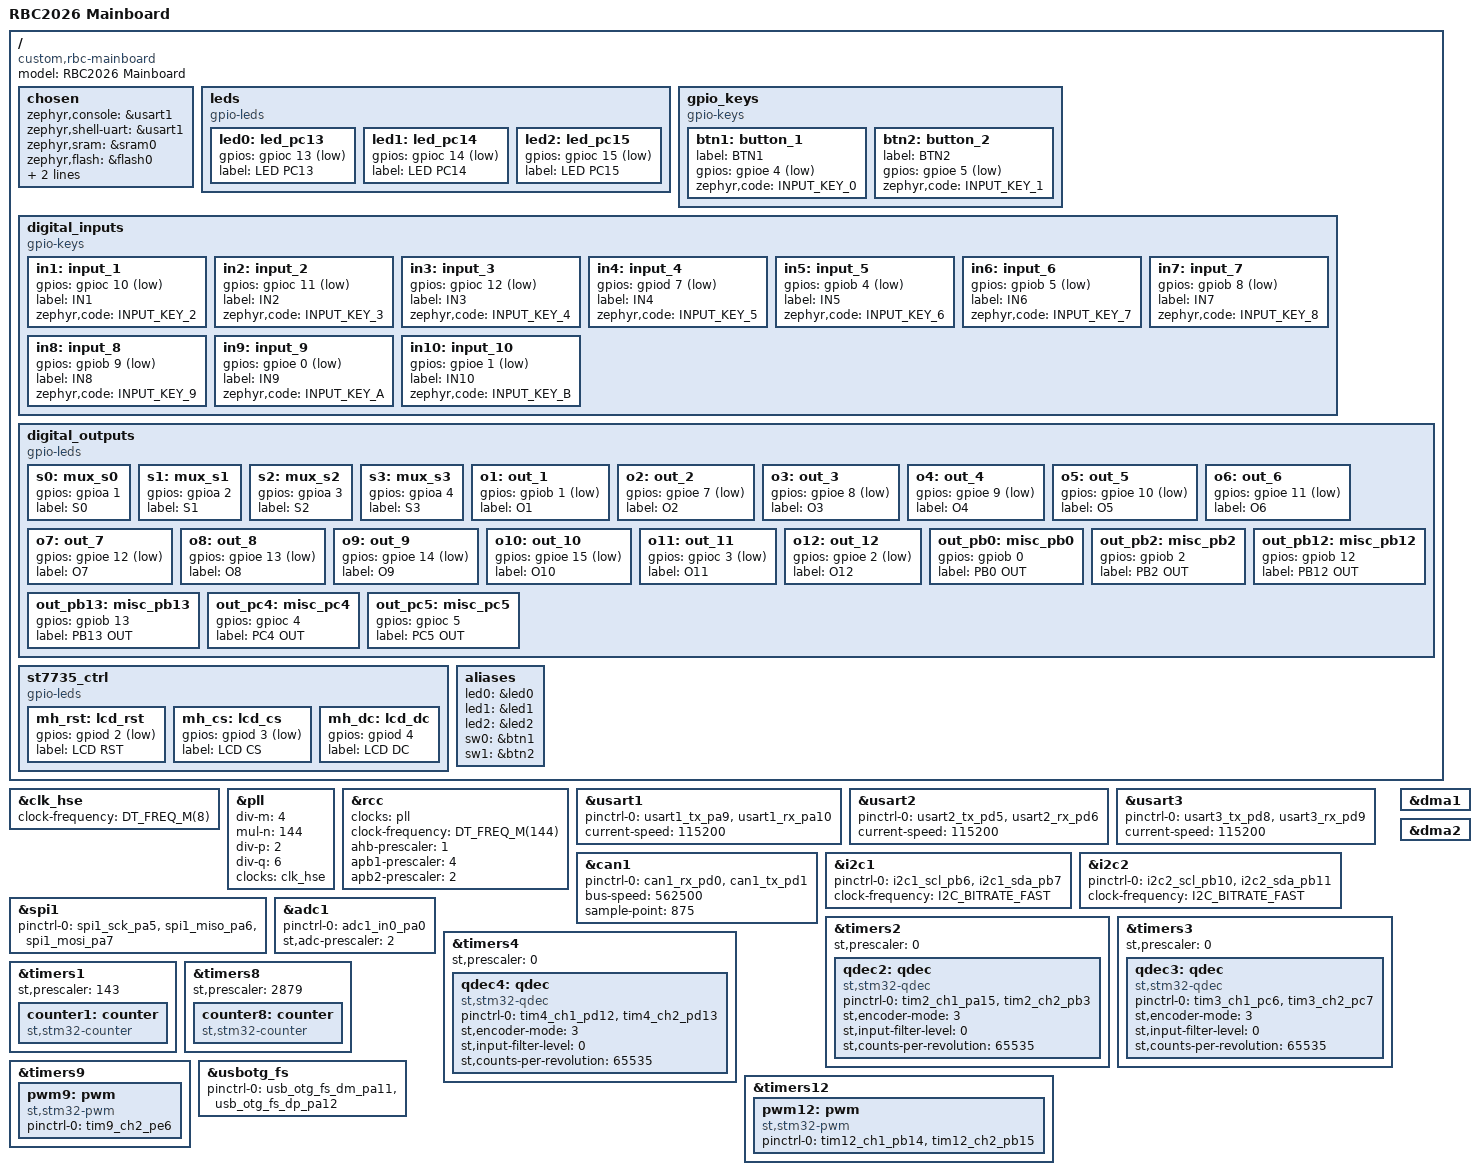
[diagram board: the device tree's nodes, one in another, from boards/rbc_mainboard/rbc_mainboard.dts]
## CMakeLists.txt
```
cmake_minimum_required(VERSION 3.20)

# Tim custom board definition trong thu muc boards/ cua project
list(APPEND BOARD_ROOT ${CMAKE_CURRENT_SOURCE_DIR})

find_package(Zephyr REQUIRED HINTS $ENV{ZEPHYR_BASE})
project(rbc_r1_blinky)

target_sources(app PRIVATE
    src/main.c
    src/bno055.c
    src/bno055_zephyr.c
    src/pca9685_zephyr.c
)

# Include src/ de bno055.c tim thay bno055.h va bno055_zephyr.h
target_include_directories(app PRIVATE src)
```

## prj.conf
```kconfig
# ── Core ──────────────────────────────────────────
CONFIG_GPIO=y
CONFIG_FPU=y
CONFIG_FPU_SHARING=y
CONFIG_CBPRINTF_FP_SUPPORT=y

# ── Compiler: toi uu toc do ──────────────────────
CONFIG_SPEED_OPTIMIZATIONS=y

# ── UART ──────────────────────────────────────────
CONFIG_SERIAL=y
CONFIG_UART_INTERRUPT_DRIVEN=y

# ── CAN ───────────────────────────────────────────
CONFIG_CAN=y

# ── I2C ───────────────────────────────────────────
CONFIG_I2C=y

# ── SPI ───────────────────────────────────────────
CONFIG_SPI=y

# ── ADC ───────────────────────────────────────────
CONFIG_ADC=y

# ── Math ──────────────────────────────────────────
# Picolibc nhe hon newlib 5-10x, la default cua Zephyr
CONFIG_PICOLIBC=y
CONFIG_PICOLIBC_IO_FLOAT=y

# ── Scheduler: multi-queue cho multi-priority tot hon ──
CONFIG_SCHED_MULTIQ=y

# ── Stack / Heap ──────────────────────────────────
# main thread: chi LED blink, giam stack
CONFIG_MAIN_STACK_SIZE=512
CONFIG_HEAP_MEM_POOL_SIZE=2048

# ── Atomic support ────────────────────────────────
# Da co san trong Zephyr kernel, khong can them config
# CONFIG_ATOMIC_OPERATIONS_BUILTIN enabled by default

# ── Thread name (de debug voi Zephyr shell) ────────
CONFIG_THREAD_NAME=y

# ── Log: tat trong production (giam latency) ──────
CONFIG_LOG=n
```

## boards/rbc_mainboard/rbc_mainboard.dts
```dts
/*
 * RBC2026 Mainboard - Custom board definition
 * Chip: STM32F407VGT6, LQFP100, HSE 8MHz
 * Chuyen tu file: RBC2026_MAINBOARD_OK.ioc
 *
 * SPDX-License-Identifier: Apache-2.0
 */

/dts-v1/;
#include <st/f4/stm32f407Xg.dtsi>
#include <st/f4/stm32f407v(e-g)tx-pinctrl.dtsi>
#include <zephyr/dt-bindings/input/input-event-codes.h>
#include <zephyr/dt-bindings/pwm/pwm.h>

/ {
	model = "RBC2026 Mainboard";
	compatible = "custom,rbc-mainboard";

	chosen {
		zephyr,console = &usart1;
		zephyr,shell-uart = &usart1;
		zephyr,sram = &sram0;
		zephyr,flash = &flash0;
		zephyr,dtcm = &ccm0;
		zephyr,canbus = &can1;
	};

	/*
	 * ====================
	 *  LEDs (PC13, PC14, PC15) - active LOW
	 * ====================
	 */
	leds {
		compatible = "gpio-leds";

		led0: led_pc13 {
			gpios = <&gpioc 13 GPIO_ACTIVE_LOW>;
			label = "LED PC13";
		};

		led1: led_pc14 {
			gpios = <&gpioc 14 GPIO_ACTIVE_LOW>;
			label = "LED PC14";
		};

		led2: led_pc15 {
			gpios = <&gpioc 15 GPIO_ACTIVE_LOW>;
			label = "LED PC15";
		};
	};

	/*
	 * ====================
	 *  Buttons (PE4 = btn1, PE5 = btn2)
	 * ====================
	 */
	gpio_keys {
		compatible = "gpio-keys";

		btn1: button_1 {
			label = "BTN1";
			gpios = <&gpioe 4 (GPIO_PULL_UP | GPIO_ACTIVE_LOW)>;
			zephyr,code = <INPUT_KEY_0>;
		};

		btn2: button_2 {
			label = "BTN2";
			gpios = <&gpioe 5 (GPIO_PULL_UP | GPIO_ACTIVE_LOW)>;
			zephyr,code = <INPUT_KEY_1>;
		};
	};

	/*
	 * ====================
	 *  Digital Inputs (in1..in10)
	 *  Dung cho limit switch, sensor, v.v.
	 * ====================
	 */
	digital_inputs {
		compatible = "gpio-keys";

		in1: input_1 {
			gpios = <&gpioc 10 GPIO_ACTIVE_LOW>;
			label = "IN1";
			zephyr,code = <INPUT_KEY_2>;
		};
		in2: input_2 {
			gpios = <&gpioc 11 GPIO_ACTIVE_LOW>;	
			label = "IN2";
			zephyr,code = <INPUT_KEY_3>;
		};
		in3: input_3 {
			gpios = <&gpioc 12 GPIO_ACTIVE_LOW>;
			label = "IN3";
			zephyr,code = <INPUT_KEY_4>;
		};
		in4: input_4 {
			gpios = <&gpiod 7 GPIO_ACTIVE_LOW>;
			label = "IN4";
			zephyr,code = <INPUT_KEY_5>;
		};
		in5: input_5 {
			gpios = <&gpiob 4 GPIO_ACTIVE_LOW>;
			label = "IN5";
			zephyr,code = <INPUT_KEY_6>;
		};
		in6: input_6 {
			gpios = <&gpiob 5 GPIO_ACTIVE_LOW>;
			label = "IN6";
			zephyr,code = <INPUT_KEY_7>;
		};
		in7: input_7 {
			gpios = <&gpiob 8 GPIO_ACTIVE_LOW>;
			label = "IN7";
			zephyr,code = <INPUT_KEY_8>;
		};
		in8: input_8 {
			gpios = <&gpiob 9 GPIO_ACTIVE_LOW>;
			label = "IN8";
			zephyr,code = <INPUT_KEY_9>;
		};
		in9: input_9 {
			gpios = <&gpioe 0 GPIO_ACTIVE_LOW>;
			label = "IN9";
			zephyr,code = <INPUT_KEY_A>;
		};
		in10: input_10 {
			gpios = <&gpioe 1 GPIO_ACTIVE_LOW>;
			label = "IN10";
			zephyr,code = <INPUT_KEY_B>;
		};
	};

	/*
	 * ====================
	 *  Digital Outputs (s0..s3, o1..o12)
	 *  Dung cho relay, solenoid, motor direction, v.v.
	 * ====================
	 */
	digital_outputs {
		compatible = "gpio-leds";

		/* Multiplexer select lines */
		s0: mux_s0 { gpios = <&gpioa 1 GPIO_ACTIVE_HIGH>; label = "S0"; };
		s1: mux_s1 { gpios = <&gpioa 2 GPIO_ACTIVE_HIGH>; label = "S1"; };
		s2: mux_s2 { gpios = <&gpioa 3 GPIO_ACTIVE_HIGH>; label = "S2"; };
		s3: mux_s3 { gpios = <&gpioa 4 GPIO_ACTIVE_HIGH>; label = "S3"; };

		/* General outputs */
		o1:  out_1  { gpios = <&gpiob 1 GPIO_ACTIVE_LOW>;  label = "O1"; };
		o2:  out_2  { gpios = <&gpioe 7 GPIO_ACTIVE_LOW>;  label = "O2"; };
		o3:  out_3  { gpios = <&gpioe 8 GPIO_ACTIVE_LOW>;  label = "O3"; };
		o4:  out_4  { gpios = <&gpioe 9 GPIO_ACTIVE_LOW>;  label = "O4"; };
		o5:  out_5  { gpios = <&gpioe 10 GPIO_ACTIVE_LOW>; label = "O5"; };
		o6:  out_6  { gpios = <&gpioe 11 GPIO_ACTIVE_LOW>; label = "O6"; };
		o7:  out_7  { gpios = <&gpioe 12 GPIO_ACTIVE_LOW>; label = "O7"; };
		o8:  out_8  { gpios = <&gpioe 13 GPIO_ACTIVE_LOW>; label = "O8"; };
		o9:  out_9  { gpios = <&gpioe 14 GPIO_ACTIVE_LOW>; label = "O9"; };
		o10: out_10 { gpios = <&gpioe 15 GPIO_ACTIVE_LOW>; label = "O10";};
		o11: out_11 { gpios = <&gpioc 3 GPIO_ACTIVE_LOW>; label = "O11";};
		o12: out_12 { gpios = <&gpioe 2 GPIO_ACTIVE_LOW>; label = "O12";};

		/* Misc outputs */
		out_pb0:  misc_pb0  { gpios = <&gpiob 0 GPIO_ACTIVE_HIGH>;  label = "PB0 OUT"; };
		out_pb2:  misc_pb2  { gpios = <&gpiob 2 GPIO_ACTIVE_HIGH>;  label = "PB2 OUT"; };
		out_pb12: misc_pb12 { gpios = <&gpiob 12 GPIO_ACTIVE_HIGH>; label = "PB12 OUT"; };
		out_pb13: misc_pb13 { gpios = <&gpiob 13 GPIO_ACTIVE_HIGH>; label = "PB13 OUT"; };
		out_pc4:  misc_pc4  { gpios = <&gpioc 4 GPIO_ACTIVE_HIGH>;  label = "PC4 OUT"; };
		out_pc5:  misc_pc5  { gpios = <&gpioc 5 GPIO_ACTIVE_HIGH>;  label = "PC5 OUT"; };
	};

	/*
	 * ====================
	 *  ST7735 LCD control pins (SPI1 + GPIO)
	 * ====================
	 */
	st7735_ctrl {
		compatible = "gpio-leds";
		mh_rst: lcd_rst { gpios = <&gpiod 2 GPIO_ACTIVE_LOW>;  label = "LCD RST"; };
		mh_cs:  lcd_cs  { gpios = <&gpiod 3 GPIO_ACTIVE_LOW>;  label = "LCD CS"; };
		mh_dc:  lcd_dc  { gpios = <&gpiod 4 GPIO_ACTIVE_HIGH>; label = "LCD DC"; };
	};

	/*
	 * ====================
	 *  Aliases
	 * ====================
	 */
	aliases {
		led0 = &led0;
		led1 = &led1;
		led2 = &led2;
		sw0 = &btn1;
		sw1 = &btn2;
	};
};

/*
 * ====================
 *  Clock: HSE 8MHz -> PLL -> SYSCLK 144MHz
 *  (IOC: PLLM=4, PLLN=144, PLLP=2 -> 8/4*144/2 = 144MHz)
 *  APB1 = 36MHz (/4), APB2 = 72MHz (/2)
 * ====================
 */
&clk_hse {
	clock-frequency = <DT_FREQ_M(8)>;
	status = "okay";
};

&pll {
	div-m = <4>;
	mul-n = <144>;
	div-p = <2>;
	div-q = <6>;
	clocks = <&clk_hse>;
	status = "okay";
};

&rcc {
	clocks = <&pll>;
	clock-frequency = <DT_FREQ_M(144)>;
	ahb-prescaler = <1>;
	apb1-prescaler = <4>;
	apb2-prescaler = <2>;
};

/*
 * ====================
 *  USART1: PA9(TX) PA10(RX) - Console/Debug
 * ====================
 */
&usart1 {
	pinctrl-0 = <&usart1_tx_pa9 &usart1_rx_pa10>;
	pinctrl-names = "default";
	current-speed = <115200>;
	status = "okay";
};

/*
 * ====================
 *  USART2: PD5(TX) PD6(RX) - HC12 / ESP
 * ====================
 */
&usart2 {
	pinctrl-0 = <&usart2_tx_pd5 &usart2_rx_pd6>;
	pinctrl-names = "default";
	current-speed = <115200>;
	status = "okay";
};

/*
 * ====================
 *  USART3: PD8(TX) PD9(RX) - DMA RX
 * ====================
 */
&usart3 {
	pinctrl-0 = <&usart3_tx_pd8 &usart3_rx_pd9>;
	pinctrl-names = "default";
	current-speed = <115200>;
	status = "okay";
};

/*
 * ====================
 *  CAN1: PD0(RX) PD1(TX)
 *  IOC: Prescaler=4, BS1=13TQ, BS2=2TQ -> 562.5kbps @ APB1=36MHz
 * ====================
 */
&can1 {
	pinctrl-0 = <&can1_rx_pd0 &can1_tx_pd1>;
	pinctrl-names = "default";
	status = "okay";

	bus-speed = <562500>;
	sample-point = <875>;
};

/*
 * ====================
 *  I2C1: PB6(SCL) PB7(SDA) - IMU
 * ====================
 */
&i2c1 {
	pinctrl-0 = <&i2c1_scl_pb6 &i2c1_sda_pb7>;
	pinctrl-names = "default";
	clock-frequency = <I2C_BITRATE_FAST>;
	status = "okay";
};

/*
 * ====================
 *  I2C2: PB10(SCL) PB11(SDA) - PCA9685
 * ====================
 */
&i2c2 {
	pinctrl-0 = <&i2c2_scl_pb10 &i2c2_sda_pb11>;
	pinctrl-names = "default";
	clock-frequency = <I2C_BITRATE_FAST>;
	status = "okay";
};

/*
 * ====================
 *  SPI1: PA5(SCK) PA6(MISO) PA7(MOSI) - LCD ST7735
 * ====================
 */
&spi1 {
	pinctrl-0 = <&spi1_sck_pa5 &spi1_miso_pa6 &spi1_mosi_pa7>;
	pinctrl-names = "default";
	status = "okay";
};

/*
 * ====================
 *  ADC1: PA0 (IN0) - Analog input
 * ====================
 */
&adc1 {
	pinctrl-0 = <&adc1_in0_pa0>;
	pinctrl-names = "default";
	st,adc-prescaler = <2>;
	status = "okay";
};

/*
 * ====================
 *  Encoders: TIM2(PA15,PB3), TIM3(PC6,PC7), TIM4(PD12,PD13)
 *  Dung Encoder mode TI12
 * ====================
 */
&timers2 {
	status = "okay";
	st,prescaler = <0>;

	qdec2: qdec {
		compatible = "st,stm32-qdec";
		status = "okay";
		pinctrl-0 = <&tim2_ch1_pa15 &tim2_ch2_pb3>;
		pinctrl-names = "default";
		st,encoder-mode = <3>;
		st,input-filter-level = <0>;
		st,counts-per-revolution = <65535>;
	};
};

&timers3 {
	status = "okay";
	st,prescaler = <0>;

	qdec3: qdec {
		compatible = "st,stm32-qdec";
		status = "okay";
		pinctrl-0 = <&tim3_ch1_pc6 &tim3_ch2_pc7>;
		pinctrl-names = "default";
		st,encoder-mode = <3>;
		st,input-filter-level = <0>;
		st,counts-per-revolution = <65535>;
	};
};

&timers4 {
	status = "okay";
	st,prescaler = <0>;

	qdec4: qdec {
		compatible = "st,stm32-qdec";
		status = "okay";
		pinctrl-0 = <&tim4_ch1_pd12 &tim4_ch2_pd13>;
		pinctrl-names = "default";
		st,encoder-mode = <3>;
		st,input-filter-level = <0>;
		st,counts-per-revolution = <65535>;
	};
};

/*
 * ====================
 *  TIM1: Internal clock, Period=9999, Prescaler=143
 *  -> IRQ freq = 144MHz / (143+1) / (9999+1) = 100Hz
 * ====================
 */
&timers1 {
	status = "okay";
	st,prescaler = <143>;

	counter1: counter {
		compatible = "st,stm32-counter";
		status = "okay";
	};
};

/*
 * ====================
 *  TIM8: Internal clock, Period=9999, Prescaler=2879
 *  -> IRQ freq = 144MHz / (2879+1) / (9999+1) = 5Hz
 * ====================
 */
&timers8 {
	status = "okay";
	st,prescaler = <2879>;

	counter8: counter {
		compatible = "st,stm32-counter";
		status = "okay";
	};
};

/*
 * ====================
 *  TIM9: PWM CH2 on PE6 (Servo / Buzzer)
 * ====================
 */
&timers9 {
	status = "okay";

	pwm9: pwm {
		compatible = "st,stm32-pwm";
		status = "okay";
		pinctrl-0 = <&tim9_ch2_pe6>;
		pinctrl-names = "default";
		#pwm-cells = <3>;
	};
};

/*
 * ====================
 *  TIM12: PWM CH1(PB14), CH2(PB15) - Motor PWM
 * ====================
 */
&timers12 {
	status = "okay";

	pwm12: pwm {
		compatible = "st,stm32-pwm";
		status = "okay";
		pinctrl-0 = <&tim12_ch1_pb14 &tim12_ch2_pb15>;
		pinctrl-names = "default";
		#pwm-cells = <3>;
	};
};

/*
 * ====================
 *  USB OTG FS: PA11(DM) PA12(DP) - CDC
 * ====================
 */
zephyr_udc0: &usbotg_fs {
	pinctrl-0 = <&usb_otg_fs_dm_pa11 &usb_otg_fs_dp_pa12>;
	pinctrl-names = "default";
	status = "okay";
};

/*
 * ====================
 *  DMA
 * ====================
 */
&dma1 {
	status = "okay";
};

&dma2 {
	status = "okay";
};
```

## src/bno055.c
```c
#include "bno055.h"
#include <string.h>

uint16_t accelScale = 100;
uint16_t tempScale = 1;
uint16_t angularRateScale = 32;//32
uint16_t eulerScale = 16;
uint16_t magScale = 16;
uint16_t quaScale = (1<<14);    // 2^14

void bno055_setPage(uint8_t page) { bno055_writeData(BNO055_PAGE_ID, page); }

bno055_opmode_t bno055_getOperationMode() {
  bno055_opmode_t mode;
  bno055_readData(BNO055_OPR_MODE, &mode, 1);
  return mode;
}

void bno055_setOperationMode(bno055_opmode_t mode) {
  bno055_writeData(BNO055_OPR_MODE, mode);
  if (mode == BNO055_OPERATION_MODE_CONFIG) {
    bno055_delay(19);
  } else {
    bno055_delay(7);
  }
}

void bno055_setOperationModeConfig() {
  bno055_setOperationMode(BNO055_OPERATION_MODE_CONFIG);
}

void bno055_setOperationModeNDOF() {
  bno055_setOperationMode(BNO055_OPERATION_MODE_NDOF);
}

void bno055_setExternalCrystalUse(bool state) {
  bno055_setPage(0);
  uint8_t tmp = 0;
  bno055_readData(BNO055_SYS_TRIGGER, &tmp, 1);
  tmp |= (state == true) ? 0x80 : 0x0;
  bno055_writeData(BNO055_SYS_TRIGGER, tmp);
  bno055_delay(700);
}

void bno055_enableExternalCrystal() { bno055_setExternalCrystalUse(true); }
void bno055_disableExternalCrystal() { bno055_setExternalCrystalUse(false); }

void bno055_reset() {
  bno055_writeData(BNO055_SYS_TRIGGER, 0x20);
  bno055_delay(700);
}

int8_t bno055_getTemp() {
  bno055_setPage(0);
  uint8_t t;
  bno055_readData(BNO055_TEMP, &t, 1);
  return t;
}

void bno055_setup() {
  bno055_reset();

  uint8_t id = 0;
  bno055_readData(BNO055_CHIP_ID, &id, 1);
  if (id != BNO055_ID) {
//    printf("Can't find BNO055, id: 0x%02x. Please check your wiring.\r\n", id);
  }
  bno055_setPage(0);
  bno055_writeData(BNO055_SYS_TRIGGER, 0x0);

  // Select BNO055 config mode
  bno055_setOperationModeConfig();
  bno055_delay(10);
}

int16_t bno055_getSWRevision() {
  bno055_setPage(0);
  uint8_t buffer[2];
  bno055_readData(BNO055_SW_REV_ID_LSB, buffer, 2);
  return (int16_t)((buffer[1] << 8) | buffer[0]);
}

uint8_t bno055_getBootloaderRevision() {
  bno055_setPage(0);
  uint8_t tmp;
  bno055_readData(BNO055_BL_REV_ID, &tmp, 1);
  return tmp;
}

uint8_t bno055_getSystemStatus() {
  bno055_setPage(0);
  uint8_t tmp;
  bno055_readData(BNO055_SYS_STATUS, &tmp, 1);
  return tmp;
}

bno055_self_test_result_t bno055_getSelfTestResult() {
  bno055_setPage(0);
  uint8_t tmp;
  bno055_self_test_result_t res = {
      .mcuState = 0, .gyrState = 0, .magState = 0, .accState = 0};
  bno055_readData(BNO055_ST_RESULT, &tmp, 1);
  res.mcuState = (tmp >> 3) & 0x01;
  res.gyrState = (tmp >> 2) & 0x01;
  res.magState = (tmp >> 1) & 0x01;
  res.accState = (tmp >> 0) & 0x01;
  return res;
}

uint8_t bno055_getSystemError() {
  bno055_setPage(0);
  uint8_t tmp;
  bno055_readData(BNO055_SYS_ERR, &tmp, 1);
  return tmp;
}

bno055_calibration_state_t bno055_getCalibrationState() {
  bno055_setPage(0);
  bno055_calibration_state_t cal = {.sys = 0, .gyro = 0, .mag = 0, .accel = 0};
  uint8_t calState = 0;
  bno055_readData(BNO055_CALIB_STAT, &calState, 1);
  cal.sys = (calState >> 6) & 0x03;
  cal.gyro = (calState >> 4) & 0x03;
  cal.accel = (calState >> 2) & 0x03;
  cal.mag = calState & 0x03;
  return cal;
}


bno055_calibration_data_t bno055_getCalibrationData() {
  bno055_calibration_data_t calData;
  uint8_t buffer[22];
  bno055_opmode_t operationMode = bno055_getOperationMode();
  bno055_setOperationModeConfig();
  bno055_setPage(0);

  bno055_readData(BNO055_ACC_OFFSET_X_LSB, buffer, 22);

  // Assumes little endian processor
  memcpy(&calData.offset.accel, buffer, 6);
  memcpy(&calData.offset.mag, buffer + 6, 6);
  memcpy(&calData.offset.gyro, buffer + 12, 6);
  memcpy(&calData.radius.accel, buffer + 18, 2);
  memcpy(&calData.radius.mag, buffer + 20, 2);

  bno055_setOperationMode(operationMode);

  return calData;
}

void bno055_setCalibrationData(bno055_calibration_data_t calData) {
  uint8_t buffer[22];
  bno055_opmode_t operationMode = bno055_getOperationMode();
  bno055_setOperationModeConfig();
  bno055_setPage(0);

  // Assumes litle endian processor
  memcpy(buffer, &calData.offset.accel, 6);
  memcpy(buffer + 6, &calData.offset.mag, 6);
  memcpy(buffer + 12, &calData.offset.gyro, 6);
  memcpy(buffer + 18, &calData.radius.accel, 2);
  memcpy(buffer + 20, &calData.radius.mag, 2);

  for (uint8_t i=0; i < 22; i++) {
    // TODO(oliv4945): create multibytes write
    bno055_writeData(BNO055_ACC_OFFSET_X_LSB+i, buffer[i]);
  }

  bno055_setOperationMode(operationMode);
}

bno055_vector_t bno055_getVector(uint8_t vec) {
  bno055_setPage(0);
  uint8_t buffer[8];    // Quaternion need 8 bytes

  if (vec == BNO055_VECTOR_QUATERNION)
    bno055_readData(vec, buffer, 8);
  else
    bno055_readData(vec, buffer, 6);

  double scale = 1;

  if (vec == BNO055_VECTOR_MAGNETOMETER) {
    scale = magScale;
  } else if (vec == BNO055_VECTOR_ACCELEROMETER ||
           vec == BNO055_VECTOR_LINEARACCEL || vec == BNO055_VECTOR_GRAVITY) {
    scale = accelScale;
  } else if (vec == BNO055_VECTOR_GYROSCOPE) {
    scale = angularRateScale;
  } else if (vec == BNO055_VECTOR_EULER) {
    scale = eulerScale;
  } else if (vec == BNO055_VECTOR_QUATERNION) {
    scale = quaScale;
  }

  bno055_vector_t xyz = {.w = 0, .x = 0, .y = 0, .z = 0};
  if (vec == BNO055_VECTOR_QUATERNION) {
    xyz.w = (int16_t)((buffer[1] << 8) | buffer[0]) / scale;
    xyz.x = (int16_t)((buffer[3] << 8) | buffer[2]) / scale;
    xyz.y = (int16_t)((buffer[5] << 8) | buffer[4]) / scale;
    xyz.z = (int16_t)((buffer[7] << 8) | buffer[6]) / scale;
  } else {
    xyz.x = (int16_t)((buffer[1] << 8) | buffer[0]) / scale;
    xyz.y = (int16_t)((buffer[3] << 8) | buffer[2]) / scale;
    xyz.z = (int16_t)((buffer[5] << 8) | buffer[4]) / scale;
  }

  return xyz;
}

bno055_vector_t bno055_getVectorAccelerometer() {
  return bno055_getVector(BNO055_VECTOR_ACCELEROMETER);
}
bno055_vector_t bno055_getVectorMagnetometer() {
  return bno055_getVector(BNO055_VECTOR_MAGNETOMETER);
}
bno055_vector_t bno055_getVectorGyroscope() {
  return bno055_getVector(BNO055_VECTOR_GYROSCOPE);
}
bno055_vector_t bno055_getVectorEuler() {
  return bno055_getVector(BNO055_VECTOR_EULER);
}
bno055_vector_t bno055_getVectorLinearAccel() {
  return bno055_getVector(BNO055_VECTOR_LINEARACCEL);
}
bno055_vector_t bno055_getVectorGravity() {
  return bno055_getVector(BNO055_VECTOR_GRAVITY);
}
bno055_vector_t bno055_getVectorQuaternion() {
  return bno055_getVector(BNO055_VECTOR_QUATERNION);
}

void bno055_setAxisMap(bno055_axis_map_t axis) {
  uint8_t axisRemap = (axis.z << 4) | (axis.y << 2) | (axis.x);
  uint8_t axisMapSign = (axis.x_sign << 2) | (axis.y_sign << 1) | (axis.z_sign);
  bno055_writeData(BNO055_AXIS_MAP_CONFIG, axisRemap);
  bno055_writeData(BNO055_AXIS_MAP_SIGN, axisMapSign);
}
```

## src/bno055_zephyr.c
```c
/*
 * bno055_zephyr.c
 * HAL binding cho BNO055 su dung Zephyr I2C API.
 * Tra ve int de caller biet loi I2C.
 */
#include "bno055_zephyr.h"
#include <zephyr/kernel.h>

static const struct i2c_dt_spec *_bno055_i2c = NULL;

void bno055_assignI2C(const struct i2c_dt_spec *i2c_dev)
{
    _bno055_i2c = i2c_dev;
}

void bno055_delay(int ms)
{
    k_msleep(ms);
}

/* Tra ve 0 neu thanh cong, am neu loi I2C */
void bno055_writeData(uint8_t reg, uint8_t data)
{
    if (!_bno055_i2c) return;
    uint8_t buf[2] = {reg, data};
    (void)i2c_write_dt(_bno055_i2c, buf, sizeof(buf));
}

void bno055_readData(uint8_t reg, uint8_t *data, uint8_t len)
{
    if (!_bno055_i2c) return;
    (void)i2c_write_read_dt(_bno055_i2c, &reg, 1, data, len);
}
```

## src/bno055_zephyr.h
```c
/*
 * bno055_zephyr.h
 * Port lop HAL binding sang Zephyr I2C API.
 * Cac ham duoc khai bao trong bno055.h la non-static, nen day chi chua
 * include guards va khai bao extern. Dinh nghia thuc te trong bno055_zephyr.c
 */
#ifndef BNO055_ZEPHYR_H
#define BNO055_ZEPHYR_H

#include <zephyr/drivers/i2c.h>
#include "bno055.h"

/* Gan con tro I2C truoc khi goi bat ky ham bno055 nao */
void bno055_assignI2C(const struct i2c_dt_spec *i2c_dev);

#endif /* BNO055_ZEPHYR_H */
```

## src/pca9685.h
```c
/*
 * pca9685.h - Ported to Zephyr I2C API
 */

#ifndef PCA9685_H_
#define PCA9685_H_

#include <zephyr/drivers/i2c.h>

/* PCA9685 I2C address (7-bit): 0x40. Trong HAL la 0x80 (shift left 1) */
#define PCA9685_I2C_ADDRESS_1  0x82  /* 8-bit addr (7-bit = 0x41), A0=HIGH */
#define FREQUENCY_OSCILLATOR   25000000

#define MODE1_RESTART  0x80
#define MODE1_SLEEP    0x10
#define MODE1_AI       0x20
#define MODE1_EXTCLK   0x40
#define MODE2_OUTDRV   0x04
#define PRESCALE_MIN   3
#define PRESCALE_MAX   255

/* Ham Zephyr (su dung i2c_dt_spec) */
void PCA9685_Init_Z(const struct i2c_dt_spec *i2c, uint8_t addr);
void PCA9685_SetPWMFreq_Z(const struct i2c_dt_spec *i2c, uint8_t addr, float freq);
void PCA9685_SetPWM_Z(const struct i2c_dt_spec *i2c, uint8_t addr,
                       uint8_t num, uint16_t on, uint16_t off);

#endif /* PCA9685_H_ */
```

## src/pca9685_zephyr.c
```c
/*
 * pca9685_zephyr.c
 * Port PCA9685 driver tu HAL sang Zephyr I2C API
 *
 * Fix: Init them MODE1_AI + MODE2_OUTDRV, sua SetPWMFreq sequence
 */
#include "pca9685.h"
#include <zephyr/drivers/i2c.h>
#include <zephyr/kernel.h>

static void PCA9685_Write8(const struct i2c_dt_spec *i2c, uint8_t addr,
                            uint8_t reg, uint8_t data)
{
    uint8_t buf[2] = {reg, data};
    /* addr trong HAL la 8-bit (7-bit << 1), trong Zephyr i2c_dt_spec da co addr 7-bit */
    (void)addr; /* Dung addr trong i2c_dt_spec */
    i2c_write_dt(i2c, buf, sizeof(buf));
}

static uint8_t PCA9685_Read8(const struct i2c_dt_spec *i2c, uint8_t addr,
                               uint8_t reg)
{
    uint8_t result = 0;
    (void)addr;
    i2c_write_read_dt(i2c, &reg, 1, &result, 1);
    return result;
}

void PCA9685_Init_Z(const struct i2c_dt_spec *i2c, uint8_t addr)
{
    /* Reset PCA9685 */
    PCA9685_Write8(i2c, addr, 0x00, MODE1_RESTART);
    k_msleep(10);

    /* MODE1: Auto-Increment ON (bat buoc de ghi nhieu register lien tiep)
     * Gia tri: 0x20 = AI bit. Khong set SLEEP -> chip bat dau chay */
    PCA9685_Write8(i2c, addr, 0x00, MODE1_AI);
    k_msleep(1);

    /* MODE2: Totem-pole output (OUTDRV=1) - can thiet cho servo
     * Neu khong set -> output la open-drain, servo khong nhan duoc tin hieu */
    PCA9685_Write8(i2c, addr, 0x01, MODE2_OUTDRV);
}

void PCA9685_SetPWMFreq_Z(const struct i2c_dt_spec *i2c, uint8_t addr,
                            float freq)
{
    /* Khong dung 0.9 compensation - SERVOMIN/SERVOMAX da calibrate cho 50Hz thuc */
    float prescaleval = FREQUENCY_OSCILLATOR / (freq * 4096.0f) - 1.0f;
    uint8_t prescale = (uint8_t)(prescaleval + 0.5f);

    /* Prescale chi co the ghi khi SLEEP=1 */
    uint8_t oldmode = PCA9685_Read8(i2c, addr, 0x00);

    /* Buoc 1: Vao SLEEP mode (giu AI neu dang bat) */
    uint8_t sleepmode = (oldmode & ~MODE1_RESTART) | MODE1_SLEEP;
    PCA9685_Write8(i2c, addr, 0x00, sleepmode);

    /* Buoc 2: Ghi prescale (chi hop le khi SLEEP=1) */
    PCA9685_Write8(i2c, addr, 0xFE, prescale);

    /* Buoc 3: Wake up - clear SLEEP, giu AI */
    uint8_t newmode = (oldmode & ~MODE1_SLEEP) | MODE1_AI;
    PCA9685_Write8(i2c, addr, 0x00, newmode);
    k_msleep(5);  /* doi oscillator on dinh (datasheet: 500us min) */

    /* Buoc 4: RESTART de bat dau PWM output */
    PCA9685_Write8(i2c, addr, 0x00, newmode | MODE1_RESTART);
}

void PCA9685_SetPWM_Z(const struct i2c_dt_spec *i2c, uint8_t addr,
                       uint8_t num, uint16_t on, uint16_t off)
{
    PCA9685_Write8(i2c, addr, 0x06 + 4 * num, on & 0xFF);
    PCA9685_Write8(i2c, addr, 0x07 + 4 * num, on >> 8);
    PCA9685_Write8(i2c, addr, 0x08 + 4 * num, off & 0xFF);
    PCA9685_Write8(i2c, addr, 0x09 + 4 * num, off >> 8);
}
```
